# NUC1xx_registers register map
File version: 0.1
CPU: 
Registers are 32-bit, read-write, reset 0x0 unless marked. A register's access mark holds for its fields unless they carry their own. Offsets are from the block's base; [hi:lo] are bit positions; lines under a group give offsets from that group.

## I2S — Registers group
Base 0x401A0000
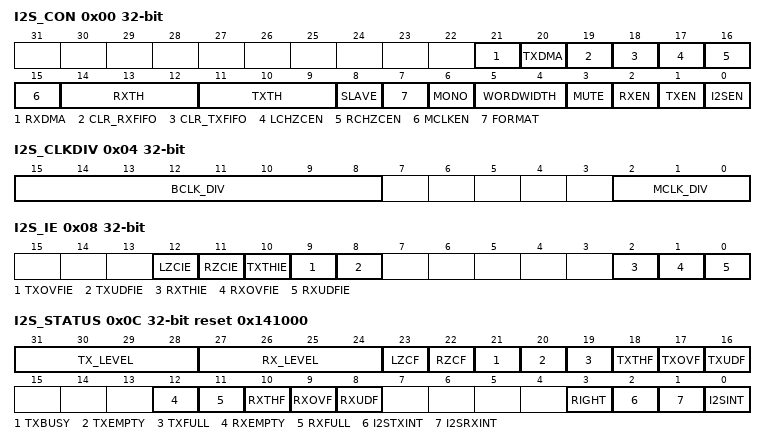
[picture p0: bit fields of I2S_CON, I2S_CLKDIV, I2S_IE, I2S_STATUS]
0x00 I2S_CON — I2S Control Register
  [21] RXDMA — Enable Receive DMA When RX DMA is enabled, I2S requests DMA to transfer data from receive FIFO to SRAM if FIFO is not empty. 1 = Enable RX DMA 0 = Disable RX DMA
  [20] TXDMA — Enable Transmit DMA When TX DMA is enabled, I2S requests DMA to transfer data from SRAM to transmit FIFO if FIFO is not full. 1 = Enable TX DMA 0 = Disable TX DMA
  [19] CLR_RXFIFO — Clear Receive FIFO Write 1 to clear receive FIFO, internal pointer is reset to FIFO start point, and RXFIFO_LEVEL[3:0] returns to zero and receive FIFO becomes empty. This bit is clear by hardware automatically, read it return zero.
  [18] CLR_TXFIFO — Clear Transmit FIFO Write 1 to clear transmit FIFO, internal pointer is reset to FIFO start point, and TXFIFO_LEVEL[3:0] returns to zero and transmit FIFO becomes empty but data in transmit FIFO is not changed. This bit is clear by hardware automatically, read it return zero.
  [17] LCHZCEN — Left channel zero cross detect enable If this bit is set to 1, when left channel data sign bit change or next shift data bits are all zero then LZCF flag in I2S_STATUS register is set to 1. 1 = Enable left channel zero cross detect 0 = Disable left channel zero cross detect
  [16] RCHZCEN — Right channel zero cross detect enable If this bit is set to 1, when left channel data sign bit change or next shift data bits are all zero then RZCF flag in I2S_STATUS register is set to 1. 1 = Enable right channel zero cross detect 0 = Disable right channel zero cross detect
  [15] MCLKEN — Master Clock Enable If NuMicro(TM) NUC100 series external crystal clock is frequency 2*N*256fs then software can program MCLK_DIV[2:0] in I2S_CLKDIV register to get 256fs clock to audio codec chip. 1 = Enable master clock 0 = Disable master clock
  [14:12] RXTH — Receive FIFO Threshold Level When received data word(s) in buffer is equal or higher than threshold level then RXTHI flag is set. 000 = 1 word data in receive FIFO 001 = 2 word data in receive FIFO 010 = 3 word data in receive FIFO 011 = 4 word data in receive FIFO 100 = 5 word data in receive FIFO 101 = 6 word data in receive FIFO 110 = 7 word data in receive FIFO 111 = 8 word data in receive FIFO
  [11:9] TXTH — Transmit FIFO Threshold Level If remain data word (32 bits) in transmit FIFO is the same or less than threshold level then TXTHI flag is set. 000 = 0 word data in transmit FIFO 001 = 1 word data in transmit FIFO 010 = 2 words data in transmit FIFO 011 = 3 words data in transmit FIFO 100 = 4 word data in transmit FIFO 101 = 5 word data in transmit FIFO 110 = 6 word data in transmit FIFO 111 = 7 word data in transmit FIFO
  [8] SLAVE — Slave Mode I2S can operate as master or slave. For master mode, I2S_BCLK and I2S_LRCLK pins are output mode and send bit clock from NuMicro(TM) NUC100 series to Audio CODEC chip. In slave mode, I2S_BCLK and I2S_LRCLK pins are input mode and I2S_BCLK and I2S_LRCLK signals are received from outer Audio CODEC chip. 1 = Slave mode 0 = Master mode
  [7] FORMAT — Data Format 1 = MSB justified data format 0 = I2S data format
  [6] MONO — Monaural Data 1 = Data is monaural format 0 = Data is stereo format
  [5:4] WORDWIDTH — Word Width 00 = data is 8 bit 01 = data is 16 bit 10 = data is 24 bit 11 = data is 32 bit
  [3] MUTE — Transmit Mute Enable 1 = Transmit channel zero 0 = Transmit data is shifted from buffer
  [2] RXEN — Receive Enable 1 = Enable data receive 0 = Disable data receive
  [1] TXEN — Transmit Enable 1 = Enable data transmit 0 = Disable data transmit
  [0] I2SEN — Enable I2S Controller 1 = Enable 0 = Disable
0x04 I2S_CLKDIV — I2S Clock Divider Register
  [15:8] BCLK_DIV — Bit Clock Divider If I2S operates in master mode, bit clock is provided by NuMicro(TM) NUC100 series. Software can program these bits to generate sampling rate clock frequency. F_BCLK = F_I2SCLK /(2x(BCLK_DIV + 1))
  [2:0] MCLK_DIV — Master Clock Divider If chip external crystal frequency is (2xMCLK_DIV)*256fs then software can program these bits to generate 256fs clock frequency to audio codec chip. If MCLK_DIV is set to 0, MCLK is the same as external clock input. For example, sampling rate is 24 kHz and chip external crystal clock is 12.288 MHz, set MCLK_DIV=1. F_MCLK = F_I2SCLK/(2x(MCLK_DIV)) (When MCLK_DIV is >= 1 ) F_MCLK = F_I2SCLK (When MCLK_DIV is set to 0 )
0x08 I2S_IE — I2S Interrupt Enable Register
  [12] LZCIE — Left channel zero cross interrupt enable Interrupt occurs if this bit is set to 1 and left channel zero cross. 1 = Enable interrupt 0 = Disable interrupt
  [11] RZCIE — Right channel zero cross interrupt enable Interrupt occurs if this bit is set to 1 and right channel zero cross. 1 = Enable interrupt 0 = Disable interrupt
  [10] TXTHIE — Transmit FIFO threshold level interrupt enable Interrupt occurs if this bit is set to 1 and data words in transmit FIFO is less than TXTH[2:0]. 1 = Enable interrupt 0 = Disable interrupt
  [9] TXOVFIE — Transmit FIFO overflow interrupt enable Interrupt occurs if this bit is set to 1 and transmit FIFO overflow flag is set to 1. 1 = Enable interrupt 0 = Disable interrupt
  [8] TXUDFIE — Transmit FIFO underflow interrupt enable Interrupt occurs if this bit is set to 1 and transmit FIFO underflow flag is set to 1. 1 = Enable interrupt 0 = Disable interrupt
  [2] RXTHIE — Receive FIFO threshold level interrupt When data word in receive FIFO is equal or higher then RXTH[2:0] and the RXTHI bit is set to 1. If RXTHIE bit is enabled, interrupt occur. 1 = Enable interrupt 0 = Disable interrupt
  [1] RXOVFIE — Receive FIFO overflow interrupt enable 1 = Enable interrupt 0 = Disable interrupt
  [0] RXUDFIE — Receive FIFO underflow interrupt enable If software read receive FIFO when it is empty then RXUDF flag in I2SSTATUS register is set to 1. 1 = Enable interrupt 0 = Disable interrupt
0x0C I2S_STATUS reset 0x141000 (reset mask 0xFFEBEFFF)
  [31:28] TX_LEVEL ro — Transmit FIFO level These bits indicate word number in Transmit FIFO. 0000 = No data 0001 = 1 word in Transmit FIFO 0010 = 2 word in Transmit FIFO 0011 = 3 word in Transmit FIFO 0100 = 4 word in Transmit FIFO 0101 = 5 word in Transmit FIFO 0110 = 6 word in Transmit FIFO 0111 = 7 word in Transmit FIFO 1000 = 8 word in Transmit FIFO
  [27:24] RX_LEVEL ro — Receive FIFO level These bits indicate word number in receive FIFO. 0000 = No data 0001 = 1 word in receive FIFO 0010 = 2 word in receive FIFO 0011 = 3 word in receive FIFO 0100 = 4 word in receive FIFO 0101 = 5 word in receive FIFO 0110 = 6 word in receive FIFO 0111 = 7 word in receive FIFO 1000 = 8 word in receive FIFO
  [23] LZCF write-1-clears — Left channel zero cross flag It indicates left channel next sample data sign bit is changed or all data bits are zero. 1 = Left channel zero cross is detected 0 = No zero cross Software can write 1 to clear this bit to zero.
  [22] RZCF write-1-clears — Right channel zero cross flag It indicates right channel next sample data sign bit is changed or all data bits are zero. 1 = Right channel zero cross is detected 0 = No zero cross Software can write 1 to clear this bit to zero.
  [21] TXBUSY ro — Transmit Busy This bit is clear to 0 when all data in transmit FIFO and shift buffer is shifted out. And set to 1 when 1st data is load to shift buffer. 1 = Transmit shift buffer is busy 0 = Transmit shift buffer is empty This bit is read only.
  [20] TXEMPTY ro — Transmit FIFO empty This bit reflect data word number in transmit FIFO is zero. 1 = Empty 0 = Not empty This bit is read only.
  [19] TXFULL ro — Transmit FIFO full This bit reflect data word number in transmit FIFO is 8. 1 = Full 0 = Not full This bit is read only.
  [18] TXTHF ro — Transmit FIFO threshold flag When data word(s) in transmit FIFO is equal or lower than threshold value set in TXTH[2:0] the TXTHF bit becomes to 1. It keeps at 1 till TXFIFO_LEVEL[3:0] is higher than TXTH[1:0] after software write TXFIFO register. 1 = Data word(s) in FIFO is equal or lower than threshold level 0 = Data word(s) in FIFO is higher than threshold level This bit is read only.
  [17] TXOVF write-1-clears — Transmit FIFO overflow flag Write data to transmit FIFO when it is full and this bit set to 1. 1 = Overflow 0 = No overflow Software can write 1 to clear this bit.
  [16] TXUDF write-1-clears — Transmit FIFO underflow flag When transmit FIFO is empty and shift logic hardware read data from data FIFO causes this set to 1. 1 = Underflow 0 = No underflow Software can write 1 to clear this bit.
  [12] RXEMPTY ro — Receive FIFO empty This bit reflects data words number in receive FIFO is zero. 1 = Empty 0 = Not empty This bit is read only.
  [11] RXFULL ro — Receive FIFO full This bit reflect data words number in receive FIFO is 8. 1 = Full 0 = Not full This bit is read only.
  [10] RXTHF ro — Receive FIFO threshold flag When data word(s) in receive FIFO is equal or higher than threshold value set in RXTH[2:0] the RXTHF bit becomes to 1. It keeps at 1 till RXFIFO_LEVEL[3:0] less than RXTH[1:0] after software read RXFIFO register. 1 = Data word(s) in FIFO is equal or higher than threshold level 0 = Data word(s) in FIFO is lower than threshold level This bit is read only.
  [9] RXOVF write-1-clears — Receive FIFO overflow flag When receive FIFO is full and receive hardware attempt write to data into receive FIFO then this bit is set to 1, data in 1st buffer is overwrote. 1 = Overflow occur 0 = No overflow occur Write 1 to clear this bit.
  [8] RXUDF write-1-clears — Receive FIFO underflow flag Read receive FIFO when it is empty, this bit set to 1 indicate underflow occur. 1 = Underflow occur 0 = No underflow occur Write 1 to clear this bit.
  [3] RIGHT ro — Right channel This bit indicate current transmit data is belong to right channel. 1 = Right channel 0 = Left channel This bit is read only.
  [2] I2STXINT ro — I2S transmit interrupt 1 = Transmit interrupt 0 = No transmit interrupt This bit is read only
  [1] I2SRXINT ro — I2S receive interrupt 1 = Receive interrupt 0 = No receive interrupt This bit is read only
  [0] I2SINT ro — I2S Interrupt flag 1 = I2S interrupt 0 = No I2S interrup It is wire-OR of I2STXINT and I2SRXINT bits. This bit is read only.
0x10 I2S_TXFIFO wo — I2S Transmit FIFO Register
  [31:0] TXFIFO — Transmit FIFO register I2S contains 8 words (8x32 bit) data buffer for data transmit. Write data to this register to prepare data for transmit. The remain word number is indicated by TX_LEVEL[3:0] in I2S_STATUS.
0x14 I2S_RXFIFO ro — I2S Receive FIFO Register
  [31:0] RXFIFO — Receive FIFO register I2S contains 8 words (8x32 bit) data buffer for data receive. Read this register to get data in FIFO. The remaining data word number is indicated by RX_LEVEL[3:0] in I2S_STATUS register.
